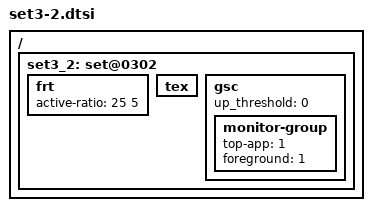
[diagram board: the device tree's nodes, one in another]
/ {
	/* game mode - app boost */
	set3_2: set@0302{
		frt {	   			/* LIT BIG */
			active-ratio 		= < 25   5>;
		};

		tex { };

		gsc {
			up_threshold = <0>;

			monitor-group {
				top-app = <1>;
				foreground = <1>;
			};
		};
	};
};
